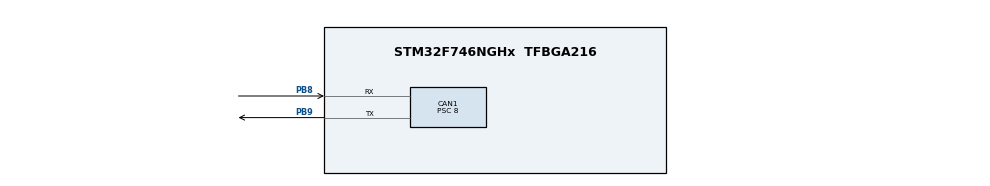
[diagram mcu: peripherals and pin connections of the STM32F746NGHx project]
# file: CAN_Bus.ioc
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CAN1.BS1=CAN_BS1_2TQ
CAN1.CalculateBaudRate=500000
CAN1.CalculateTimeBit=2000
CAN1.CalculateTimeQuantum=500.0
CAN1.Prescaler=8
Mcu.Family=STM32F7
Mcu.Name=STM32F746NGHx
Mcu.Package=TFBGA216
NVIC.CAN1_RX0_IRQn=true\:0\:0\:false\:false\:true\:true\:true\:true
NVIC.PriorityGroup=NVIC_PRIORITYGROUP_4
PB8.GPIO_PuPd=GPIO_NOPULL
PB8.Mode=CAN_Activate
PB8.Signal=CAN1_RX
PB9.GPIO_PuPd=GPIO_NOPULL
PB9.Mode=CAN_Activate
PB9.Signal=CAN1_TX
ProjectManager.HeapSize=0x200
ProjectManager.StackSize=0x400
ProjectManager.TargetToolchain=STM32CubeIDE
RCC.HSE_VALUE=25000000
RCC.HSI_VALUE=16000000
RCC.LSE_VALUE=32768
RCC.USBFreq_Value=96000000
RCC.VCOOutputFreq_Value=192000000
board=custom

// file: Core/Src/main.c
/* USER CODE BEGIN Header */
/**
  ******************************************************************************
  * @file           : main.c
  * @brief          : Main program body
  ******************************************************************************
  * @attention
  *
  * Copyright (c) 2024 STMicroelectronics.
  * All rights reserved.
  *
  * This software is licensed under terms that can be found in the LICENSE file
  * in the root directory of this software component.
  * If no LICENSE file comes with this software, it is provided AS-IS.
  *
  ******************************************************************************
  */
/* USER CODE END Header */
#include "main.h"
#include "stdbool.h"

CAN_HandleTypeDef hcan1;

void SystemClock_Config(void);
static void MX_GPIO_Init(void);
static void MX_CAN1_Init(void);

/* USER CODE BEGIN 0 */
CAN_TxHeaderTypeDef   TxHeader;
uint8_t               TxData[8];
uint32_t              TxMailbox;
CAN_RxHeaderTypeDef   RxHeader;
uint8_t               RxData[8];

typedef struct
{
	uint16_t RPM_M1;
	uint16_t RPM_M2;
	uint16_t RPM_M3;
	bool     Stat_M1;
	bool     Stat_M2;
	bool     Stat_M3;
	bool     Fault_M1;
	bool     Fault_M2;
	bool     Fault_M3;
} rotation_stats_t;

typedef struct
{
	uint16_t T_Chip;
	uint16_t T_M1;
	uint16_t T_M2;
	uint16_t T_M3;
} temp_stats_t;

rotation_stats_t rot_stats;
temp_stats_t     temp_stats;

void send_can_data()
{
	TxHeader.IDE = CAN_ID_STD;
	TxHeader.RTR = CAN_RTR_DATA;
	TxHeader.StdId = 0x001;
	TxHeader.DLC = 8;

	TxData[0] = 0x03;
	TxData[1] = 0xE8;
	TxData[2] = 0x03;
	TxData[3] = 0xE8;
	TxData[4] = 0x03;
	TxData[5] = 0xE8;
	TxData[6] = 0x77;
	TxData[7] = 0x22;

	HAL_CAN_Start(&hcan1);

	if (HAL_CAN_AddTxMessage(&hcan1, &TxHeader, TxData, &TxMailbox) != HAL_OK)
	{
	   Error_Handler ();
	}

	CAN_FilterTypeDef canfilterconfig;

	canfilterconfig.FilterActivation = CAN_FILTER_ENABLE;
	canfilterconfig.FilterFIFOAssignment = CAN_FILTER_FIFO0;
	canfilterconfig.FilterIdHigh = 0;
	canfilterconfig.FilterIdLow = 0;
	canfilterconfig.FilterMaskIdHigh = 0;
	canfilterconfig.FilterMaskIdLow = 0;
	canfilterconfig.FilterMode = CAN_FILTERMODE_IDMASK;
	canfilterconfig.FilterScale = CAN_FILTERSCALE_32BIT;
	canfilterconfig.SlaveStartFilterBank = 14;  // how many filters to assign to the CAN1 (master can
	canfilterconfig.FilterBank = 0;  // which filter bank to use from the assigned ones

	HAL_CAN_ConfigFilter(&hcan1, &canfilterconfig);

	if (HAL_CAN_ActivateNotification(&hcan1, CAN_IT_RX_FIFO0_MSG_PENDING) != HAL_OK)
	{
	  Error_Handler();
	}

	while (1)
	{
		HAL_Delay(5000);
		HAL_CAN_AddTxMessage(&hcan1, &TxHeader, TxData, &TxMailbox);
	}

}

void HAL_CAN_RxFifo0MsgPendingCallback(CAN_HandleTypeDef *hcan)
{
	if (HAL_CAN_GetRxMessage(hcan, CAN_RX_FIFO0, &RxHeader, RxData) != HAL_OK)
	{
		Error_Handler();
	}
	else
	{
		if (RxHeader.StdId == 2)
		{
			rot_stats.RPM_M1   = (RxData[0] << 8) | RxData[1];
			rot_stats.RPM_M2   = (RxData[2] << 8) | RxData[3];
			rot_stats.RPM_M3   = (RxData[4] << 8) | RxData[5];
			rot_stats.Stat_M1  = ((RxData[6] & 0x10) >> 4) ;
			rot_stats.Stat_M2  = ((RxData[6] & 0x20) >> 5);
			rot_stats.Stat_M3  = ((RxData[6] & 0x40) >> 6);
			rot_stats.Fault_M3 = RxData[6] & 0xF;
			rot_stats.Fault_M2 = ((RxData[7] & 0xF0) >> 4);
			rot_stats.Fault_M1 = (RxData[7] & 0x0F);
		}
		if (RxHeader.StdId == 3)
		{
			temp_stats.T_Chip = (RxData[0] << 8) | RxData[1];
			temp_stats.T_M1   = (RxData[2] << 8) | RxData[3];
			temp_stats.T_M2   = (RxData[4] << 8) | RxData[5];
			temp_stats.T_M3   = (RxData[6] << 8) | RxData[7];
		}
	}
}
/* USER CODE END 0 */

int main(void)
{

  /* MCU Configuration--------------------------------------------------------*/

  /* Reset of all peripherals, Initializes the Flash interface and the Systick. */
  HAL_Init();

  /* Configure the system clock */
  SystemClock_Config();

  /* Initialize all configured peripherals */
  MX_GPIO_Init();
  MX_CAN1_Init();
  /* USER CODE BEGIN 2 */
  send_can_data();
  /* USER CODE END 2 */

  /* Infinite loop */
  while (1)
  {

  }
}

void SystemClock_Config(void)
{
  RCC_OscInitTypeDef RCC_OscInitStruct = {0};
  RCC_ClkInitTypeDef RCC_ClkInitStruct = {0};

  /** Configure the main internal regulator output voltage
  */
  __HAL_RCC_PWR_CLK_ENABLE();
  __HAL_PWR_VOLTAGESCALING_CONFIG(PWR_REGULATOR_VOLTAGE_SCALE3);

  /** Initializes the RCC Oscillators according to the specified parameters
  * in the RCC_OscInitTypeDef structure.
  */
  RCC_OscInitStruct.OscillatorType = RCC_OSCILLATORTYPE_HSI;
  RCC_OscInitStruct.HSIState = RCC_HSI_ON;
  RCC_OscInitStruct.HSICalibrationValue = RCC_HSICALIBRATION_DEFAULT;
  RCC_OscInitStruct.PLL.PLLState = RCC_PLL_NONE;
  if (HAL_RCC_OscConfig(&RCC_OscInitStruct) != HAL_OK)
  {
    Error_Handler();
  }

  /** Initializes the CPU, AHB and APB buses clocks
  */
  RCC_ClkInitStruct.ClockType = RCC_CLOCKTYPE_HCLK|RCC_CLOCKTYPE_SYSCLK
                              |RCC_CLOCKTYPE_PCLK1|RCC_CLOCKTYPE_PCLK2;
  RCC_ClkInitStruct.SYSCLKSource = RCC_SYSCLKSOURCE_HSI;
  RCC_ClkInitStruct.AHBCLKDivider = RCC_SYSCLK_DIV1;
  RCC_ClkInitStruct.APB1CLKDivider = RCC_HCLK_DIV1;
  RCC_ClkInitStruct.APB2CLKDivider = RCC_HCLK_DIV1;

  if (HAL_RCC_ClockConfig(&RCC_ClkInitStruct, FLASH_LATENCY_0) != HAL_OK)
  {
    Error_Handler();
  }
}

static void MX_CAN1_Init(void)
{

  hcan1.Instance = CAN1;
  hcan1.Init.Prescaler = 8;
  hcan1.Init.Mode = CAN_MODE_NORMAL;
  hcan1.Init.SyncJumpWidth = CAN_SJW_1TQ;
  hcan1.Init.TimeSeg1 = CAN_BS1_2TQ;
  hcan1.Init.TimeSeg2 = CAN_BS2_1TQ;
  hcan1.Init.TimeTriggeredMode = DISABLE;
  hcan1.Init.AutoBusOff = DISABLE;
  hcan1.Init.AutoWakeUp = DISABLE;
  hcan1.Init.AutoRetransmission = DISABLE;
  hcan1.Init.ReceiveFifoLocked = DISABLE;
  hcan1.Init.TransmitFifoPriority = DISABLE;
  if (HAL_CAN_Init(&hcan1) != HAL_OK)
  {
    Error_Handler();
  }

}

static void MX_GPIO_Init(void)
{

  /* GPIO Ports Clock Enable */
  __HAL_RCC_GPIOB_CLK_ENABLE();

}

void Error_Handler(void)
{
  __disable_irq();
  while (1)
  {
  }
}
